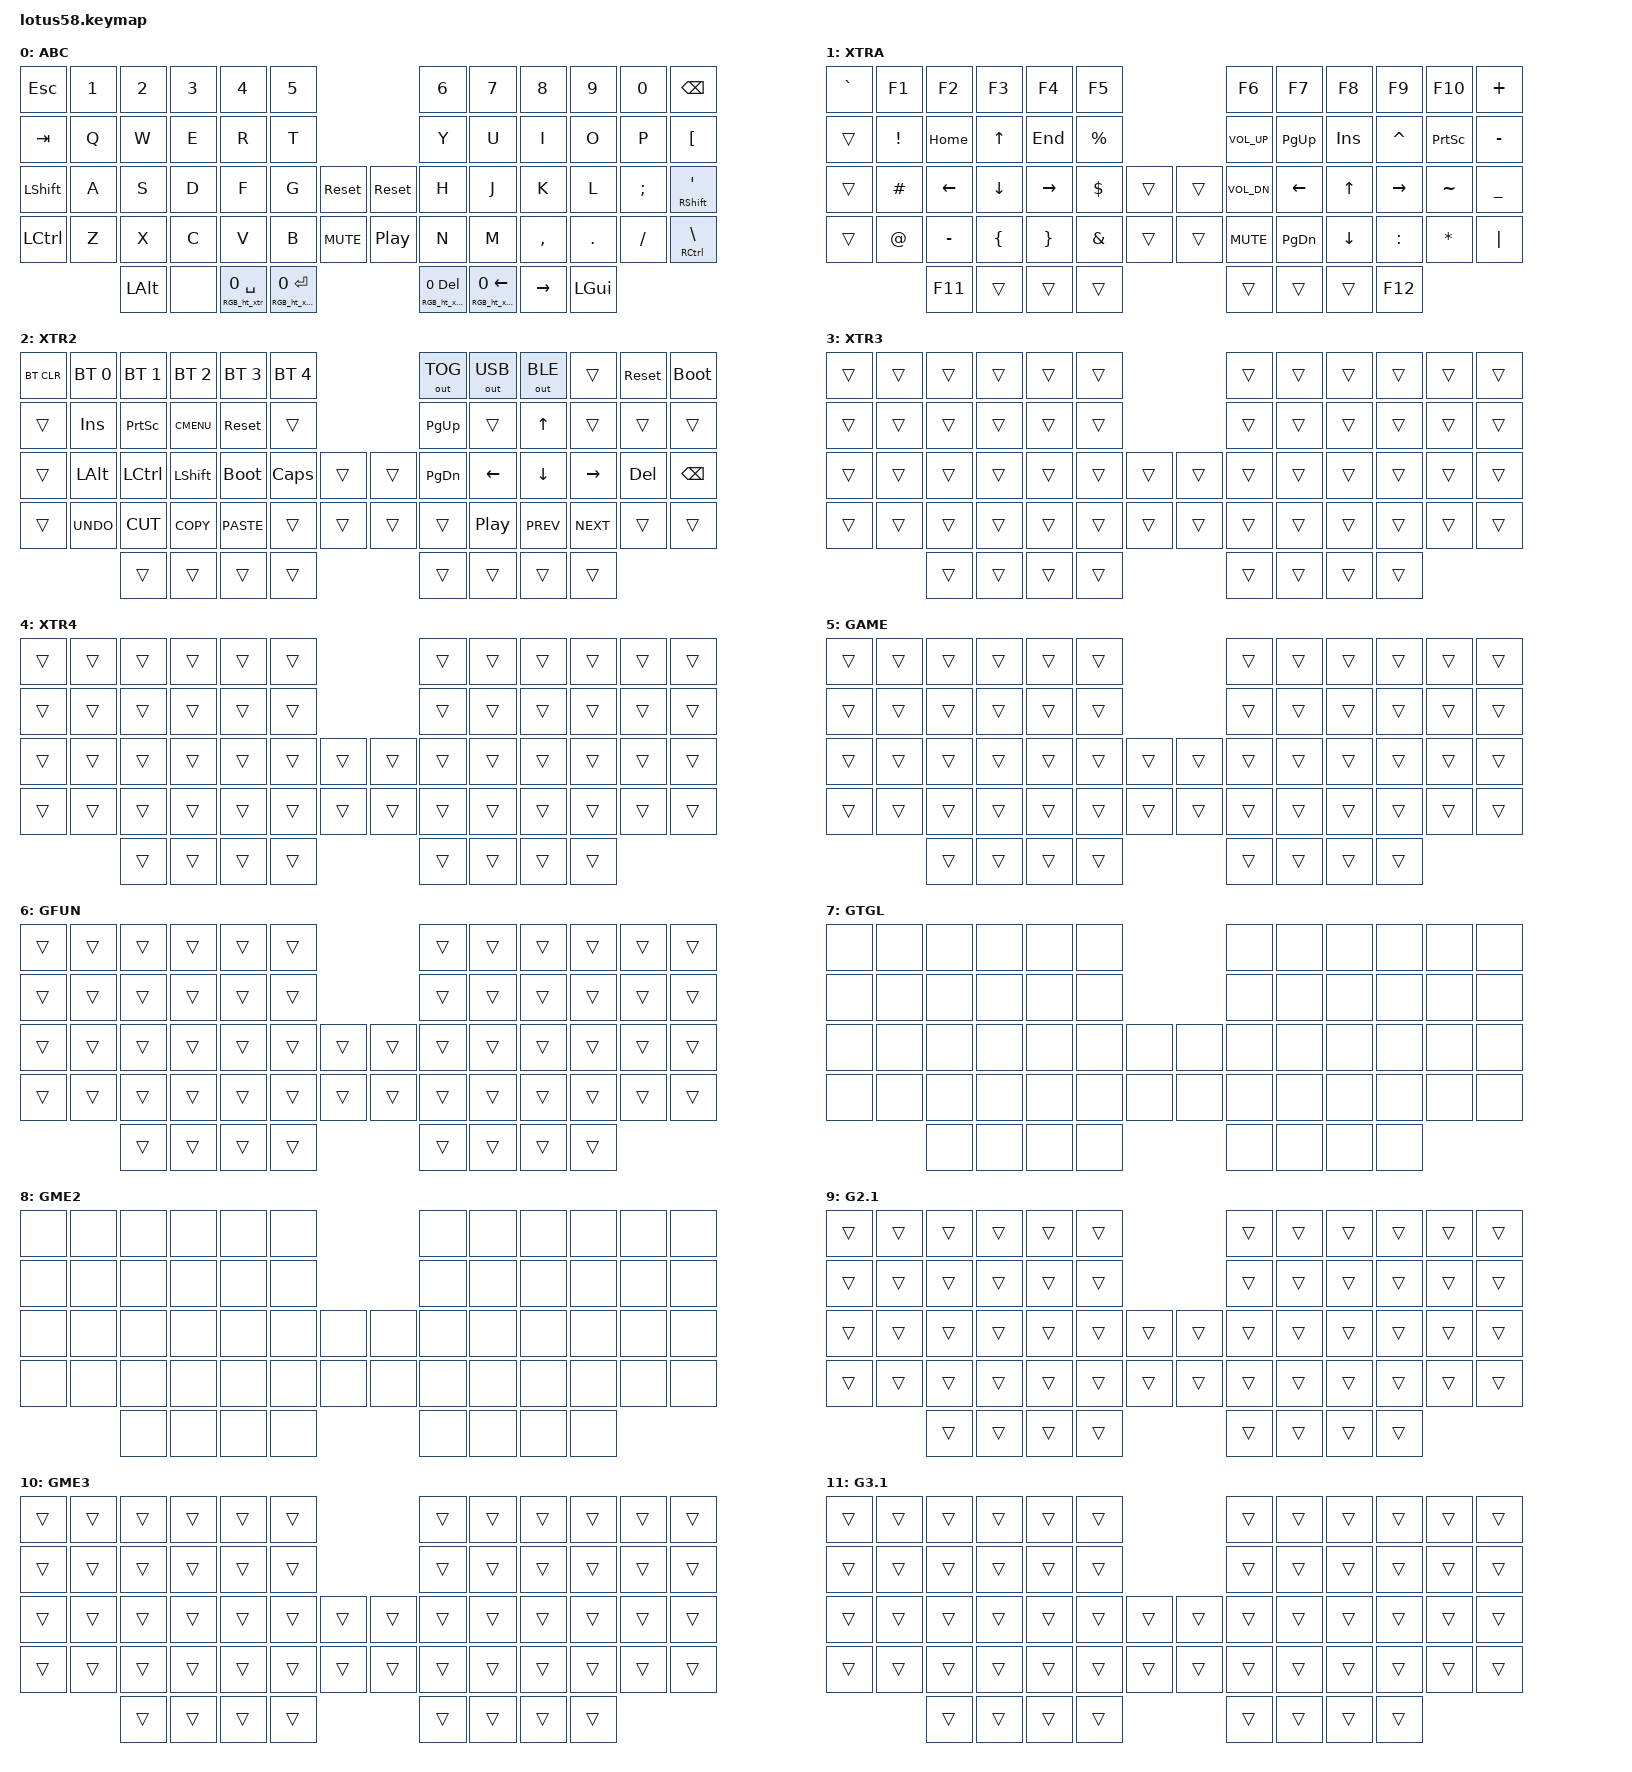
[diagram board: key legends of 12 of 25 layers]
/*
 * Copyright (c) 2022 The ZMK Contributors
 *
 * SPDX-License-Identifier: MIT
 */
#include <behaviors.dtsi>
#include <dt-bindings/zmk/bt.h>
#include <dt-bindings/zmk/keys.h>
#include <dt-bindings/zmk/outputs.h>
#include <dt-bindings/zmk/rgb.h>
#include "lotus58-rgb.dtsi"

/ {
    combos {
        compatible = "zmk,combos";

        combo_dsklg {
            timeout-ms = <100>;
            key-positions = <24 52>;
            layers = <0>;
            bindings = <&kp LGUI>;
        };
    };

    behaviors {
        fofunc: four_ffour {
            compatible = "zmk,behavior-mod-morph";
            #binding-cells = <0>;
            bindings = <&kp N4>, <&kp F4>;

            mods = <(MOD_LALT|MOD_RALT)>;
        };

        sleft: s_left {
            compatible = "zmk,behavior-mod-morph";
            #binding-cells = <0>;
            bindings = <&kp S>, <&kp LEFT>;

            mods = <(MOD_LGUI|MOD_RGUI)>;
        };

        fright: f_right {
            compatible = "zmk,behavior-mod-morph";
            #binding-cells = <0>;
            bindings = <&kp F>, <&kp RIGHT>;

            mods = <(MOD_LGUI|MOD_RGUI)>;
        };
    };
};

/ {
    keymap {
        compatible = "zmk,keymap";

        base {
            display-name = "ABC";
            bindings = <
                &kp ESC    &kp N1  &kp N2    &kp N3  &kp N4               &kp N5                                          &kp N6                 &kp N7                &kp N8     &kp N9    &kp N0    &kp BSPC
                &kp TAB    &kp Q   &kp W     &kp E   &kp R                &kp T                                           &kp Y                  &kp U                 &kp I      &kp O     &kp P     &kp LBKT
                &kp LSHFT  &kp A   &kp S     &kp D   &kp F                &kp G                 &sys_reset    &sys_reset  &kp H                  &kp J                 &kp K      &kp L     &kp SEMI  &mt RSHFT SQT
                &kp LCTRL  &kp Z   &kp X     &kp C   &kp V                &kp B                 &kp C_MUTE    &kp C_PP    &kp N                  &kp M                 &kp COMMA  &kp DOT   &kp FSLH  &mt RCTRL BSLH
                                   &kp LALT  &none   &RGB_ht_xtr 0 SPACE  &RGB_ht_xtr2 0 ENTER                            &RGB_ht_xtr3 0 DELETE  &RGB_ht_xtra4 0 LEFT  &kp RIGHT  &kp LGUI
            >;
            sensor-bindings = <&inc_dec_kp C_VOL_DN C_VOL_UP &inc_dec_kp PG_UP PG_DN>;
        };

        extra {
            display-name = "XTRA";
            bindings = <
                &kp GRAVE  &kp F1    &kp F2     &kp F3    &kp F4     &kp F5                       &kp F6        &kp F7     &kp F8    &kp F9     &kp F10    &kp PLUS
                &trans     &kp EXCL  &kp HOME   &kp UP    &kp END    &kp PRCNT                    &kp C_VOL_UP  &kp PG_UP  &kp INS   &kp CARET  &kp PSCRN  &kp MINUS
                &trans     &kp HASH  &kp LEFT   &kp DOWN  &kp RIGHT  &kp DLLR   &trans    &trans  &kp C_VOL_DN  &kp LEFT   &kp UP    &kp RIGHT  &kp TILDE  &kp UNDER
                &trans     &kp AT    &kp MINUS  &kp LBRC  &kp RBRC   &kp AMPS   &trans    &trans  &kp C_MUTE    &kp PG_DN  &kp DOWN  &kp COLON  &kp STAR   &kp PIPE
                                     &kp F11    &trans    &trans     &trans                       &trans        &trans     &trans    &kp F12
            >;
            sensor-bindings = <&inc_dec_kp C_VOL_DN C_VOL_UP &inc_dec_kp C_NEXT C_PREV>;
        };

        extra_2 {
            display-name = "XTR2";
            bindings = <
                &bt BT_CLR  &bt BT_SEL 0  &bt BT_SEL 1  &bt BT_SEL 2  &bt BT_SEL 3  &bt BT_SEL 4                    &out OUT_TOG  &out OUT_USB  &out OUT_BLE  &trans      &sys_reset  &bootloader
                &trans      &kp INS       &kp PSCRN     &kp K_CMENU   &sys_reset    &trans                          &kp PG_UP     &trans        &kp UP        &trans      &trans      &trans
                &trans      &kp LALT      &kp LCTRL     &kp LSHFT     &bootloader   &kp CLCK      &trans    &trans  &kp PG_DN     &kp LEFT      &kp DOWN      &kp RIGHT   &kp DEL     &kp BSPC
                &trans      &kp K_UNDO    &kp K_CUT     &kp K_COPY    &kp K_PASTE   &trans        &trans    &trans  &trans        &kp C_PP      &kp C_PREV    &kp C_NEXT  &trans      &trans
                                          &trans        &trans        &trans        &trans                          &trans        &trans        &trans        &trans
            >;
            sensor-bindings = <&inc_dec_kp C_VOL_DN C_VOL_UP &inc_dec_kp PG_UP PG_DN>;
        };

        extra_3 {
            display-name = "XTR3";
            bindings = <
                &trans  &trans  &trans  &trans  &trans  &trans                    &trans  &trans  &trans  &trans  &trans  &trans
                &trans  &trans  &trans  &trans  &trans  &trans                    &trans  &trans  &trans  &trans  &trans  &trans
                &trans  &trans  &trans  &trans  &trans  &trans  &trans    &trans  &trans  &trans  &trans  &trans  &trans  &trans
                &trans  &trans  &trans  &trans  &trans  &trans  &trans    &trans  &trans  &trans  &trans  &trans  &trans  &trans
                                &trans  &trans  &trans  &trans                    &trans  &trans  &trans  &trans
            >;
        };

        extra_4 {
            display-name = "XTR4";
            bindings = <
                &trans  &trans  &trans  &trans  &trans  &trans                    &trans  &trans  &trans  &trans  &trans  &trans
                &trans  &trans  &trans  &trans  &trans  &trans                    &trans  &trans  &trans  &trans  &trans  &trans
                &trans  &trans  &trans  &trans  &trans  &trans  &trans    &trans  &trans  &trans  &trans  &trans  &trans  &trans
                &trans  &trans  &trans  &trans  &trans  &trans  &trans    &trans  &trans  &trans  &trans  &trans  &trans  &trans
                                &trans  &trans  &trans  &trans                    &trans  &trans  &trans  &trans
            >;
        };

        game {
            display-name = "GAME";
            bindings = <
                &trans  &trans  &trans  &trans  &trans  &trans                    &trans  &trans  &trans  &trans  &trans  &trans
                &trans  &trans  &trans  &trans  &trans  &trans                    &trans  &trans  &trans  &trans  &trans  &trans
                &trans  &trans  &trans  &trans  &trans  &trans  &trans    &trans  &trans  &trans  &trans  &trans  &trans  &trans
                &trans  &trans  &trans  &trans  &trans  &trans  &trans    &trans  &trans  &trans  &trans  &trans  &trans  &trans
                                &trans  &trans  &trans  &trans                    &trans  &trans  &trans  &trans
            >;
        };

        game_sub {
            display-name = "GFUN";
            bindings = <
                &trans  &trans  &trans  &trans  &trans  &trans                    &trans  &trans  &trans  &trans  &trans  &trans
                &trans  &trans  &trans  &trans  &trans  &trans                    &trans  &trans  &trans  &trans  &trans  &trans
                &trans  &trans  &trans  &trans  &trans  &trans  &trans    &trans  &trans  &trans  &trans  &trans  &trans  &trans
                &trans  &trans  &trans  &trans  &trans  &trans  &trans    &trans  &trans  &trans  &trans  &trans  &trans  &trans
                                &trans  &trans  &trans  &trans                    &trans  &trans  &trans  &trans
            >;
        };

        game_gate {
            display-name = "GTGL";
            bindings = <
                &none  &none  &none  &none  &none  &none                  &none  &none  &none  &none  &none  &none
                &none  &none  &none  &none  &none  &none                  &none  &none  &none  &none  &none  &none
                &none  &none  &none  &none  &none  &none  &none    &none  &none  &none  &none  &none  &none  &none
                &none  &none  &none  &none  &none  &none  &none    &none  &none  &none  &none  &none  &none  &none
                              &none  &none  &none  &none                  &none  &none  &none  &none
            >;
        };

        game2 {
            display-name = "GME2";
            bindings = <
                &none  &none  &none  &none  &none  &none                  &none  &none  &none  &none  &none  &none
                &none  &none  &none  &none  &none  &none                  &none  &none  &none  &none  &none  &none
                &none  &none  &none  &none  &none  &none  &none    &none  &none  &none  &none  &none  &none  &none
                &none  &none  &none  &none  &none  &none  &none    &none  &none  &none  &none  &none  &none  &none
                              &none  &none  &none  &none                  &none  &none  &none  &none
            >;
        };

        game2_sub {
            display-name = "G2.1";
            bindings = <
                &trans  &trans  &trans  &trans  &trans  &trans                    &trans  &trans  &trans  &trans  &trans  &trans
                &trans  &trans  &trans  &trans  &trans  &trans                    &trans  &trans  &trans  &trans  &trans  &trans
                &trans  &trans  &trans  &trans  &trans  &trans  &trans    &trans  &trans  &trans  &trans  &trans  &trans  &trans
                &trans  &trans  &trans  &trans  &trans  &trans  &trans    &trans  &trans  &trans  &trans  &trans  &trans  &trans
                                &trans  &trans  &trans  &trans                    &trans  &trans  &trans  &trans
            >;
        };

        game3 {
            display-name = "GME3";
            bindings = <
                &trans  &trans  &trans  &trans  &trans  &trans                    &trans  &trans  &trans  &trans  &trans  &trans
                &trans  &trans  &trans  &trans  &trans  &trans                    &trans  &trans  &trans  &trans  &trans  &trans
                &trans  &trans  &trans  &trans  &trans  &trans  &trans    &trans  &trans  &trans  &trans  &trans  &trans  &trans
                &trans  &trans  &trans  &trans  &trans  &trans  &trans    &trans  &trans  &trans  &trans  &trans  &trans  &trans
                                &trans  &trans  &trans  &trans                    &trans  &trans  &trans  &trans
            >;
        };

        game3_sub1 {
            display-name = "G3.1";
            bindings = <
                &trans  &trans  &trans  &trans  &trans  &trans                    &trans  &trans  &trans  &trans  &trans  &trans
                &trans  &trans  &trans  &trans  &trans  &trans                    &trans  &trans  &trans  &trans  &trans  &trans
                &trans  &trans  &trans  &trans  &trans  &trans  &trans    &trans  &trans  &trans  &trans  &trans  &trans  &trans
                &trans  &trans  &trans  &trans  &trans  &trans  &trans    &trans  &trans  &trans  &trans  &trans  &trans  &trans
                                &trans  &trans  &trans  &trans                    &trans  &trans  &trans  &trans
            >;
        };

        game4 {
            display-name = "GME4";
            bindings = <
                &trans  &trans  &trans  &trans  &trans  &trans                    &trans  &trans  &trans  &trans  &trans  &trans
                &trans  &trans  &trans  &trans  &trans  &trans                    &trans  &trans  &trans  &trans  &trans  &trans
                &trans  &trans  &trans  &trans  &trans  &trans  &trans    &trans  &trans  &trans  &trans  &trans  &trans  &trans
                &trans  &trans  &trans  &trans  &trans  &trans  &trans    &trans  &trans  &trans  &trans  &trans  &trans  &trans
                                &trans  &trans  &trans  &trans                    &trans  &trans  &trans  &trans
            >;
        };

        game4_sub1 {
            display-name = "G4.1";
            bindings = <
                &trans  &trans  &trans  &trans  &trans  &trans                    &trans  &trans  &trans  &trans  &trans  &trans
                &trans  &trans  &trans  &trans  &trans  &trans                    &trans  &trans  &trans  &trans  &trans  &trans
                &trans  &trans  &trans  &trans  &trans  &trans  &trans    &trans  &trans  &trans  &trans  &trans  &trans  &trans
                &trans  &trans  &trans  &trans  &trans  &trans  &trans    &trans  &trans  &trans  &trans  &trans  &trans  &trans
                                &trans  &trans  &trans  &trans                    &trans  &trans  &trans  &trans
            >;
        };

        tog_layer {
            display-name = "TOG";
            bindings = <
                &none  &none  &none  &none  &none  &none                  &none  &none  &none  &none  &none  &none
                &none  &none  &none  &none  &none  &none                  &none  &none  &none  &none  &none  &none
                &none  &none  &none  &none  &none  &none  &none    &none  &none  &none  &none  &none  &none  &none
                &none  &none  &none  &none  &none  &none  &none    &none  &none  &none  &none  &none  &none  &none
                              &none  &none  &none  &none                  &none  &none  &none  &none
            >;
        };

        sub_base1 {
            display-name = "T1";
            bindings = <
                &none  &none  &none  &none  &none  &none                  &none  &none  &none  &none  &none  &none
                &none  &none  &none  &none  &none  &none                  &none  &none  &none  &none  &none  &none
                &none  &none  &none  &none  &none  &none  &none    &none  &none  &none  &none  &none  &none  &none
                &none  &none  &none  &none  &none  &none  &none    &none  &none  &none  &none  &none  &none  &none
                              &none  &none  &none  &none                  &none  &none  &none  &none
            >;
        };

        subbase1_sublayer1 {
            display-name = "T1.1";
            bindings = <
                &trans  &trans  &trans  &trans  &trans  &trans                    &trans  &trans  &trans  &trans  &trans  &trans
                &trans  &trans  &trans  &trans  &trans  &trans                    &trans  &trans  &trans  &trans  &trans  &trans
                &trans  &trans  &trans  &trans  &trans  &trans  &trans    &trans  &trans  &trans  &trans  &trans  &trans  &trans
                &trans  &trans  &trans  &trans  &trans  &trans  &trans    &trans  &trans  &trans  &trans  &trans  &trans  &trans
                                &trans  &trans  &trans  &trans                    &trans  &trans  &trans  &trans
            >;
        };

        subbase1_sublayer2 {
            display-name = "T1.2";
            bindings = <
                &trans  &trans  &trans  &trans  &trans  &trans                    &trans  &trans  &trans  &trans  &trans  &trans
                &trans  &trans  &trans  &trans  &trans  &trans                    &trans  &trans  &trans  &trans  &trans  &trans
                &trans  &trans  &trans  &trans  &trans  &trans  &trans    &trans  &trans  &trans  &trans  &trans  &trans  &trans
                &trans  &trans  &trans  &trans  &trans  &trans  &trans    &trans  &trans  &trans  &trans  &trans  &trans  &trans
                                &trans  &trans  &trans  &trans                    &trans  &trans  &trans  &trans
            >;
        };

        sub_base1_sublayer3 {
            display-name = "T1.3";
            bindings = <
                &trans  &trans  &trans  &trans  &trans  &trans                    &trans  &trans  &trans  &trans  &trans  &trans
                &trans  &trans  &trans  &trans  &trans  &trans                    &trans  &trans  &trans  &trans  &trans  &trans
                &trans  &trans  &trans  &trans  &trans  &trans  &trans    &trans  &trans  &trans  &trans  &trans  &trans  &trans
                &trans  &trans  &trans  &trans  &trans  &trans  &trans    &trans  &trans  &trans  &trans  &trans  &trans  &trans
                                &trans  &trans  &trans  &trans                    &trans  &trans  &trans  &trans
            >;
        };

        sub_base1_sublayer4 {
            display-name = "T1.4";
            bindings = <
                &trans  &trans  &trans  &trans  &trans  &trans                    &trans  &trans  &trans  &trans  &trans  &trans
                &trans  &trans  &trans  &trans  &trans  &trans                    &trans  &trans  &trans  &trans  &trans  &trans
                &trans  &trans  &trans  &trans  &trans  &trans  &trans    &trans  &trans  &trans  &trans  &trans  &trans  &trans
                &trans  &trans  &trans  &trans  &trans  &trans  &trans    &trans  &trans  &trans  &trans  &trans  &trans  &trans
                                &trans  &trans  &trans  &trans                    &trans  &trans  &trans  &trans
            >;
        };

        sub_base2 {
            display-name = "T2";
            bindings = <
                &none  &none  &none  &none  &none  &none                  &none  &none  &none  &none  &none  &none
                &none  &none  &none  &none  &none  &none                  &none  &none  &none  &none  &none  &none
                &none  &none  &none  &none  &none  &none  &none    &none  &none  &none  &none  &none  &none  &none
                &none  &none  &none  &none  &none  &none  &none    &none  &none  &none  &none  &none  &none  &none
                              &none  &none  &none  &none                  &none  &none  &none  &none
            >;
        };

        subbase2_sublayer1 {
            display-name = "T2.1";
            bindings = <
                &trans  &trans  &trans  &trans  &trans  &trans                    &trans  &trans  &trans  &trans  &trans  &trans
                &trans  &trans  &trans  &trans  &trans  &trans                    &trans  &trans  &trans  &trans  &trans  &trans
                &trans  &trans  &trans  &trans  &trans  &trans  &trans    &trans  &trans  &trans  &trans  &trans  &trans  &trans
                &trans  &trans  &trans  &trans  &trans  &trans  &trans    &trans  &trans  &trans  &trans  &trans  &trans  &trans
                                &trans  &trans  &trans  &trans                    &trans  &trans  &trans  &trans
            >;
        };

        subbase2_sublayer2 {
            display-name = "T2.2";
            bindings = <
                &trans  &trans  &trans  &trans  &trans  &trans                    &trans  &trans  &trans  &trans  &trans  &trans
                &trans  &trans  &trans  &trans  &trans  &trans                    &trans  &trans  &trans  &trans  &trans  &trans
                &trans  &trans  &trans  &trans  &trans  &trans  &trans    &trans  &trans  &trans  &trans  &trans  &trans  &trans
                &trans  &trans  &trans  &trans  &trans  &trans  &trans    &trans  &trans  &trans  &trans  &trans  &trans  &trans
                                &trans  &trans  &trans  &trans                    &trans  &trans  &trans  &trans
            >;
        };

        subbase2_sublayer3 {
            display-name = "T2.3";
            bindings = <
                &trans  &trans  &trans  &trans  &trans  &trans                    &trans  &trans  &trans  &trans  &trans  &trans
                &trans  &trans  &trans  &trans  &trans  &trans                    &trans  &trans  &trans  &trans  &trans  &trans
                &trans  &trans  &trans  &trans  &trans  &trans  &trans    &trans  &trans  &trans  &trans  &trans  &trans  &trans
                &trans  &trans  &trans  &trans  &trans  &trans  &trans    &trans  &trans  &trans  &trans  &trans  &trans  &trans
                                &trans  &trans  &trans  &trans                    &trans  &trans  &trans  &trans
            >;
        };

        subbase2_sublayer4 {
            display-name = "T2.4";
            bindings = <
                &trans  &trans  &trans  &trans  &trans  &trans                    &trans  &trans  &trans  &trans  &trans  &trans
                &trans  &trans  &trans  &trans  &trans  &trans                    &trans  &trans  &trans  &trans  &trans  &trans
                &trans  &trans  &trans  &trans  &trans  &trans  &trans    &trans  &trans  &trans  &trans  &trans  &trans  &trans
                &trans  &trans  &trans  &trans  &trans  &trans  &trans    &trans  &trans  &trans  &trans  &trans  &trans  &trans
                                &trans  &trans  &trans  &trans                    &trans  &trans  &trans  &trans
            >;
        };
    };
};
